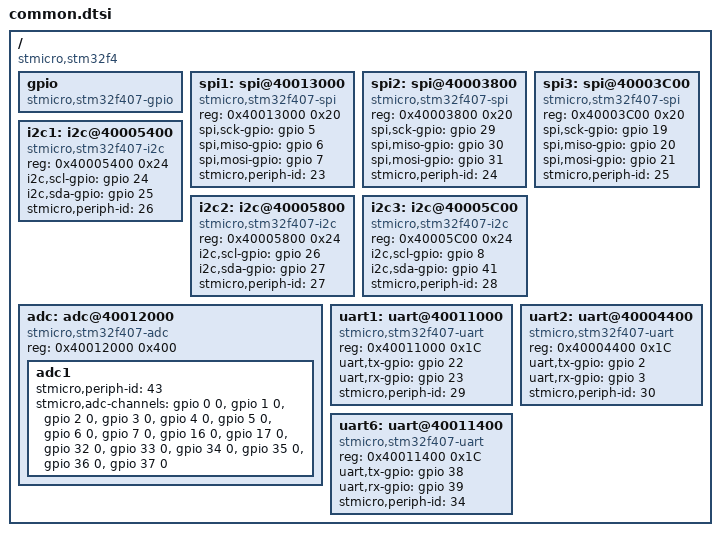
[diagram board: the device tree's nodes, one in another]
/ {
    compatible = "stmicro,stm32f4";

    #address-cells = <1>;
    #size-cells = <1>;

    gpio: gpio {
        compatible = "stmicro,stm32f407-gpio";
    };

    spi1: spi@40013000 {
        #address-cells = <1>;
        #size-cells = <0>;
        compatible = "stmicro,stm32f407-spi";
        reg = <0x40013000 0x20>;
        spi,sck-gpio = <&gpio 5 0>;     /* PA5 */
        spi,miso-gpio = <&gpio 6 0>;    /* PA6 */
        spi,mosi-gpio = <&gpio 7 0>;    /* PA7 */
        stmicro,periph-id = <23>;       /* STM32F4_PERIPH_SPI1 */
    };

    spi2: spi@40003800 {
        #address-cells = <1>;
        #size-cells = <0>;
        compatible = "stmicro,stm32f407-spi";
        reg = <0x40003800 0x20>;
        spi,sck-gpio = <&gpio 29 0>;    /* PB13 */
        spi,miso-gpio = <&gpio 30 0>;   /* PB14 */
        spi,mosi-gpio = <&gpio 31 0>;   /* PB15 */
        stmicro,periph-id = <24>;       /* STM32F4_PERIPH_SPI2 */
    };

    spi3: spi@40003C00 {
        #address-cells = <1>;
        #size-cells = <0>;
        compatible = "stmicro,stm32f407-spi";
        reg = <0x40003C00 0x20>;
        spi,sck-gpio = <&gpio 19 0>;    /* PB3 */
        spi,miso-gpio = <&gpio 20 0>;   /* PB4 */
        spi,mosi-gpio = <&gpio 21 0>;   /* PB5 */
        stmicro,periph-id = <25>;       /* STM32F4_PERIPH_SPI3 */
    };

    i2c1: i2c@40005400 {
        #address-cells = <1>;
        #size-cells = <0>;
        compatible = "stmicro,stm32f407-i2c";
        reg = <0x40005400 0x24>;
        i2c,scl-gpio = <&gpio 24 0>;    /* PB8 */
        i2c,sda-gpio = <&gpio 25 0>;    /* PB9 */
        stmicro,periph-id = <26>;       /* STM32F4_PERIPH_I2C1 */
    };

    i2c2: i2c@40005800 {
        #address-cells = <1>;
        #size-cells = <0>;
        compatible = "stmicro,stm32f407-i2c";
        reg = <0x40005800 0x24>;
        i2c,scl-gpio = <&gpio 26 0>;    /* PB10 */
        i2c,sda-gpio = <&gpio 27 0>;    /* PB11 */
        stmicro,periph-id = <27>;       /* STM32F4_PERIPH_I2C2 */
    };

    i2c3: i2c@40005C00 {
        #address-cells = <1>;
        #size-cells = <0>;
        compatible = "stmicro,stm32f407-i2c";
        reg = <0x40005C00 0x24>;
        i2c,scl-gpio = <&gpio 8 0>;     /* PA8 */
        i2c,sda-gpio = <&gpio 41 0>;    /* PC9 */
        stmicro,periph-id = <28>;       /* STM32F4_PERIPH_I2C3 */
    };

    adc: adc@40012000 {
        #address-cells = <0>;
        #size-cells = <0>;
        compatible = "stmicro,stm32f407-adc";
        reg = <0x40012000 0x400>;

        adc1 {
            stmicro,periph-id = <43>;   /* STM32F4_PERIPH_ADC1 */
            stmicro,adc-channels = <&gpio 0 0>  /* PA0 */,
                                   <&gpio 1 0>  /* PA1 */,
                                   <&gpio 2 0>  /* PA2 */,
                                   <&gpio 3 0>  /* PA3 */,
                                   <&gpio 4 0>  /* PA4 */,
                                   <&gpio 5 0>  /* PA5 */,
                                   <&gpio 6 0>  /* PA6 */,
                                   <&gpio 7 0>  /* PA7 */,
                                   <&gpio 16 0> /* PB0 */,
                                   <&gpio 17 0> /* PB1 */,
                                   <&gpio 32 0> /* PC0 */,
                                   <&gpio 33 0> /* PC1 */,
                                   <&gpio 34 0> /* PC2 */,
                                   <&gpio 35 0> /* PC3 */,
                                   <&gpio 36 0> /* PC4 */,
                                   <&gpio 37 0> /* PC5 */;
        };
    };

    uart1: uart@40011000 {
        compatible = "stmicro,stm32f407-uart";
        reg = <0x40011000 0x1C>;
        uart,tx-gpio = <&gpio 22 0>;    /* PB6 */
        uart,rx-gpio = <&gpio 23 0>;    /* PB7 */
        stmicro,periph-id = <29>;       /* STM32F4_PERIPH_USART1 */
    };

    uart2: uart@40004400 {
        compatible = "stmicro,stm32f407-uart";
        reg = <0x40004400 0x1C>;
        uart,tx-gpio = <&gpio 2 0>;     /* PA2 */
        uart,rx-gpio = <&gpio 3 0>;     /* PA3 */
        stmicro,periph-id = <30>;       /* STM32F4_PERIPH_USART2 */
    };

    uart6: uart@40011400 {
        compatible = "stmicro,stm32f407-uart";
        reg = <0x40011400 0x1C>;
        uart,tx-gpio = <&gpio 38 0>;    /* PC6 */
        uart,rx-gpio = <&gpio 39 0>;    /* PC7 */
        stmicro,periph-id = <34>;       /* STM32F4_PERIPH_USART6 */
    };
};
